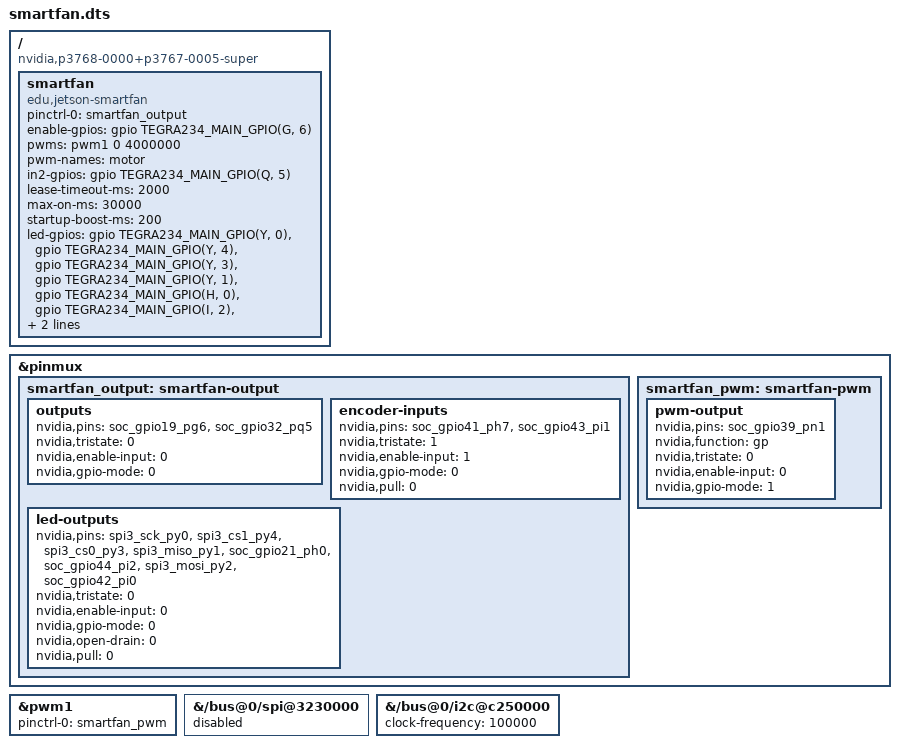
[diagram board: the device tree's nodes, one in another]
// SPDX-License-Identifier: GPL-2.0
/dts-v1/;
/plugin/;

#include <dt-bindings/gpio/gpio.h>
#include <dt-bindings/gpio/tegra234-gpio.h>

/ {
	compatible = "nvidia,p3768-0000+p3767-0005-super",
		     "nvidia,p3768-0000+p3767-0005";

	fragment@0 {
		target-path = "/";
		__overlay__ {
			smartfan {
				compatible = "edu,jetson-smartfan";
				status = "okay";
				pinctrl-names = "default";
				pinctrl-0 = <&smartfan_output>;
				/* J12 물리 32번: PG.06, gpiochip offset 41. */
				enable-gpios = <&gpio TEGRA234_MAIN_GPIO(G, 6)
						GPIO_ACTIVE_HIGH>;
				/* J12 물리 15번: PN.01, PWM1 channel0, 목표 250Hz. */
				pwms = <&pwm1 0 4000000>;
				pwm-names = "motor";
				/* J12 물리 29번: PQ.05, gpiochip offset 105. */
				in2-gpios = <&gpio TEGRA234_MAIN_GPIO(Q, 5)
					     GPIO_ACTIVE_HIGH>;
				lease-timeout-ms = <2000>;
				max-on-ms = <30000>;
				startup-boost-ms = <200>;
				/* LED 1..8은 J12 물리 13,16,18,22,33,35,37,40번 순서. */
				led-gpios = <&gpio TEGRA234_MAIN_GPIO(Y, 0) GPIO_ACTIVE_HIGH>,
					    <&gpio TEGRA234_MAIN_GPIO(Y, 4) GPIO_ACTIVE_HIGH>,
					    <&gpio TEGRA234_MAIN_GPIO(Y, 3) GPIO_ACTIVE_HIGH>,
					    <&gpio TEGRA234_MAIN_GPIO(Y, 1) GPIO_ACTIVE_HIGH>,
					    <&gpio TEGRA234_MAIN_GPIO(H, 0) GPIO_ACTIVE_HIGH>,
					    <&gpio TEGRA234_MAIN_GPIO(I, 2) GPIO_ACTIVE_HIGH>,
					    <&gpio TEGRA234_MAIN_GPIO(Y, 2) GPIO_ACTIVE_HIGH>,
					    <&gpio TEGRA234_MAIN_GPIO(I, 0) GPIO_ACTIVE_HIGH>;
			};
		};
	};

	fragment@1 {
		target = <&pinmux>;
		__overlay__ {
			smartfan_output: smartfan-output {
				outputs {
					/* 모터 ENA와 고정된 역방향 입력을 GPIO 출력으로 설정한다. */
					nvidia,pins = "soc_gpio19_pg6",
						      "soc_gpio32_pq5";
					nvidia,tristate = <0>;
					nvidia,enable-input = <0>;
					/* GPIO 모드는 PADCTL SFSEL bit=0이다. */
					nvidia,gpio-mode = <0>;
				};
				encoder-inputs {
					/* J12 물리 12/38번은 userspace만 요청하는 엔코더 입력이다. */
					nvidia,pins = "soc_gpio41_ph7", "soc_gpio43_pi1";
					nvidia,tristate = <1>;
					nvidia,enable-input = <1>;
					nvidia,gpio-mode = <0>;
					nvidia,pull = <0>;
				};
				led-outputs {
					nvidia,pins = "spi3_sck_py0", "spi3_cs1_py4",
						      "spi3_cs0_py3", "spi3_miso_py1",
						      "soc_gpio21_ph0", "soc_gpio44_pi2",
						      "spi3_mosi_py2", "soc_gpio42_pi0";
					nvidia,tristate = <0>;
					nvidia,enable-input = <0>;
					nvidia,gpio-mode = <0>;
					nvidia,open-drain = <0>;
					nvidia,pull = <0>;
				};
			};
			smartfan_pwm: smartfan-pwm {
				pwm-output {
					nvidia,pins = "soc_gpio39_pn1";
					nvidia,function = "gp";
					nvidia,tristate = <0>;
					nvidia,enable-input = <0>;
					nvidia,gpio-mode = <1>;
				};
			};
		};
	};

	fragment@2 {
		target = <&pwm1>;
		__overlay__ {
			status = "okay";
			pinctrl-names = "default";
			/* PWM runtime resume이 자신의 SFIO pad 상태를 복원해야 한다. */
			pinctrl-0 = <&smartfan_pwm>;
		};
	};
	fragment@3 {
		/* Header SPI1은 LED 1..4/7과 같은 PY pad를 사용하므로 비활성화한다. */
		target-path = "/bus@0/spi@3230000";
		__overlay__ {
			status = "disabled";
		};
	};
	fragment@4 {
		target-path = "/bus@0/i2c@c250000";
		__overlay__ {
			/* PCF8574T는 400kHz가 아닌 Standard-mode 100kHz를 사용한다. */
			clock-frequency = <100000>;
		};
	};
};
